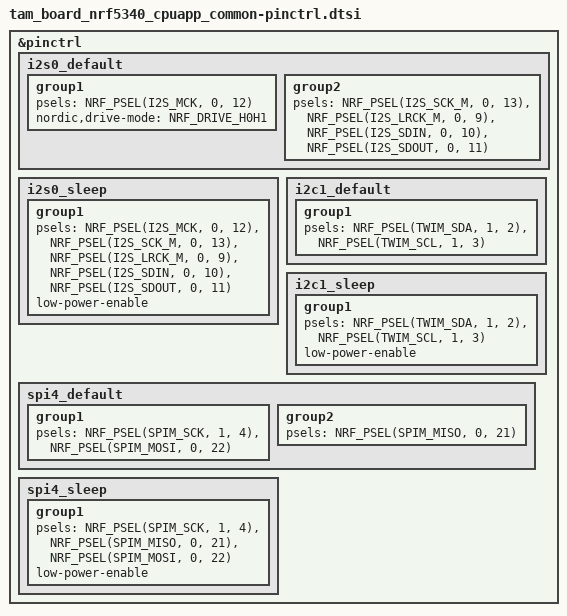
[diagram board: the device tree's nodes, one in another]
/*
 * Copyright (c) 2022 Nordic Semiconductor ASA
 *
 * SPDX-License-Identifier: Apache-2.0
 */

&pinctrl {
	i2s0_default: i2s0_default {
		group1 {
			psels = <NRF_PSEL(I2S_MCK, 0, 12)>;
			nordic,drive-mode = <NRF_DRIVE_H0H1>;
		};
		group2 {
			psels = <NRF_PSEL(I2S_SCK_M, 0, 13)>,
				<NRF_PSEL(I2S_LRCK_M, 0, 9)>,
				<NRF_PSEL(I2S_SDIN, 0, 10)>,
				<NRF_PSEL(I2S_SDOUT, 0, 11)>;
		};
	};

	i2s0_sleep: i2s0_sleep {
		group1 {
			psels = <NRF_PSEL(I2S_MCK, 0, 12)>,
				<NRF_PSEL(I2S_SCK_M, 0, 13)>,
				<NRF_PSEL(I2S_LRCK_M, 0, 9)>,
				<NRF_PSEL(I2S_SDIN, 0, 10)>,
				<NRF_PSEL(I2S_SDOUT, 0, 11)>;
			low-power-enable;
		};
	};

	i2c1_default: i2c1_default {
		group1 {
			psels = <NRF_PSEL(TWIM_SDA, 1, 2)>,
				<NRF_PSEL(TWIM_SCL, 1, 3)>;
		};
	};

	i2c1_sleep: i2c1_sleep {
		group1 {
			psels = <NRF_PSEL(TWIM_SDA, 1, 2)>,
				<NRF_PSEL(TWIM_SCL, 1, 3)>;
			low-power-enable;
		};
	};

	spi4_default: spi4_default {
		group1 {
			psels = <NRF_PSEL(SPIM_SCK, 1, 4)>,
				<NRF_PSEL(SPIM_MOSI, 0, 22)>;
		};
		group2 {
			psels = <NRF_PSEL(SPIM_MISO, 0, 21)>;
		};
	};

	spi4_sleep: spi4_sleep {
		group1 {
			psels = <NRF_PSEL(SPIM_SCK, 1, 4)>,
				<NRF_PSEL(SPIM_MISO, 0, 21)>,
				<NRF_PSEL(SPIM_MOSI, 0, 22)>;
			low-power-enable;
		};
	};
};
